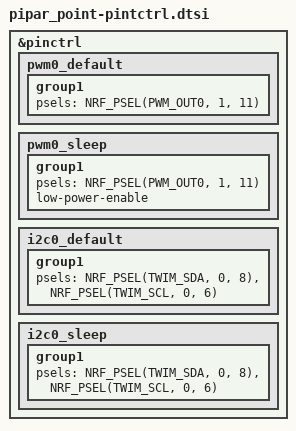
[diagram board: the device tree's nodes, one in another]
&pinctrl {
    pwm0_default: pwm0_default {
        group1 {
            psels = <NRF_PSEL(PWM_OUT0, 1, 11)>;
        };
    };

    pwm0_sleep: pwm0_sleep {
        group1 {
            psels = <NRF_PSEL(PWM_OUT0, 1, 11)>;
            low-power-enable;
        };
    };

    // I2C for nPM1300
    i2c0_default: i2c0_default {
        group1 {
            psels = <NRF_PSEL(TWIM_SDA, 0, 8)>,
                    <NRF_PSEL(TWIM_SCL, 0, 6)>;
        };
    };

    i2c0_sleep: i2c0_sleep {
        group1 {
            psels = <NRF_PSEL(TWIM_SDA, 0, 8)>,
                    <NRF_PSEL(TWIM_SCL, 0, 6)>;
        };
    };
};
